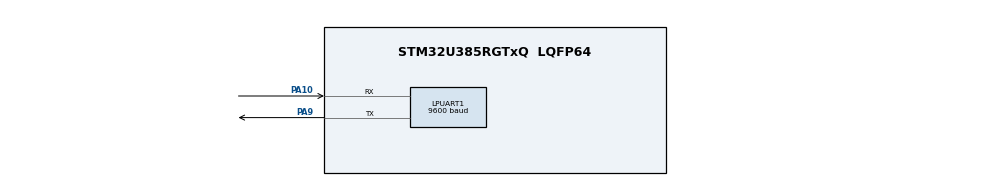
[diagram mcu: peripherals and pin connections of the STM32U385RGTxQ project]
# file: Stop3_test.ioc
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ADC1.Channel-0\#ChannelRegularConversion=ADC_CHANNEL_VREFINT
ADC1.Channel-1\#ChannelRegularConversion=ADC_CHANNEL_TEMPSENSOR
ADC1.EnableAnalogWatchDog1=false
ADC1.LowPowerAutoWait=ENABLE
ADC1.MonitoredBy-0\#ChannelRegularConversion=__NULL
ADC1.MonitoredBy-1\#ChannelRegularConversion=__NULL
ADC1.NbrOfConversion=2
ADC1.NbrOfConversionFlag=1
ADC1.OffsetNumber-0\#ChannelRegularConversion=ADC_OFFSET_NONE
ADC1.OffsetNumber-1\#ChannelRegularConversion=ADC_OFFSET_NONE
ADC1.Rank-0\#ChannelRegularConversion=1
ADC1.Rank-1\#ChannelRegularConversion=2
ADC1.SamplingTime-0\#ChannelRegularConversion=ADC_SAMPLETIME_46CYCLES_5
ADC1.SamplingTime-1\#ChannelRegularConversion=ADC_SAMPLETIME_46CYCLES_5
ADC1.master=1
CORTEX_M33_NS.userName=CORTEX_M33
LPUART1.BaudRate=9600
LPUART1.FIFOMode=UART_FIFOMODE_ENABLE
LPUART1.RXFIFOThreshold=UART_RXFIFO_THRESHOLD_8_8
LPUART1.TXFIFOThreshold=UART_TXFIFO_THRESHOLD_8_8
Mcu.Family=STM32U3
Mcu.Name=STM32U385RGTxQ
Mcu.Package=LQFP64
NVIC.LPUART1_IRQn=true\:0\:0\:false\:false\:true\:true\:true\:true
NVIC.PriorityGroup=NVIC_PRIORITYGROUP_4
NVIC.RTC_IRQn=true\:0\:0\:false\:false\:true\:true\:true\:true
PA10.Mode=Asynchronous
PA10.Signal=LPUART1_RX
PA9.Mode=Asynchronous
PA9.Signal=LPUART1_TX
PC14-OSC32_IN\ (PC14).Mode=LSE-External-Oscillator
PC14-OSC32_IN\ (PC14).Signal=RCC_OSC32_IN
PC15-OSC32_OUT\ (PC15).Mode=LSE-External-Oscillator
PC15-OSC32_OUT\ (PC15).Signal=RCC_OSC32_OUT
ProjectManager.HeapSize=0x200
ProjectManager.StackSize=0x400
ProjectManager.TargetToolchain=STM32CubeIDE
RCC.ADCFreq_Value=24000000
RCC.ADC_DIV=RCC_ADCDACCLK_DIV2
RCC.AHBFreq_Value=48000000
RCC.APB1Freq_Value=48000000
RCC.APB1TimFreq_Value=48000000
RCC.APB2Freq_Value=48000000
RCC.APB2TimFreq_Value=48000000
RCC.APB3Freq_Value=48000000
RCC.CortexFreq_Value=6000000
RCC.HCLKFreq_Value=48000000
RCC.HSE_VALUE=16000000
RCC.HSI48_VALUE=48000000
RCC.HSI_VALUE=16000000
RCC.LPUART1CLockSelection=RCC_LPUART1CLKSOURCE_LSE
RCC.LSIDIV_VALUE=32000
RCC.MSIKDIV=RCC_MSI_DIV8
RCC.MSIKSource=RCC_MSI_RC1
RCC.MSISDIV=RCC_MSI_DIV2
RCC.RTCClockSelection=RCC_RTCCLKSOURCE_LSE
RCC.SYSCLKFreq_VALUE=48000000
RCC.USBFreq_Value=48000000
RTC.WakeUpClock-WakeUp=RTC_WAKEUPCLOCK_CK_SPRE_16BITS
VP_ADC1_TempSens_Input.Mode=IN-TempSens
VP_ADC1_Vref_Input.Mode=IN-Vrefint
VP_ICACHE_VS_ICACHE.Mode=DirectMappedCache
VP_PWR_VS_DBSignals.Mode=DisableDeadBatterySignals
VP_PWR_VS_LPOM.Mode=PowerOptimisation
VP_PWR_VS_SECSignals.Mode=Security/Privilege
VP_RTC_VS_RTC_Activate.Mode=RTC_Enabled
VP_RTC_VS_RTC_WakeUp_intern.Mode=WakeUp
board=custom

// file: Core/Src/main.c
/* USER CODE BEGIN Header */
/**
  ******************************************************************************
  * @file           : main.c
  * @brief          : Main program body
  ******************************************************************************
  * @attention
  *
  * Copyright (c) 2025 STMicroelectronics.
  * All rights reserved.
  *
  * This software is licensed under terms that can be found in the LICENSE file
  * in the root directory of this software component.
  * If no LICENSE file comes with this software, it is provided AS-IS.
  *
  ******************************************************************************
  */
/* USER CODE END Header */
#include "main.h"

/* USER CODE BEGIN Includes */
#include "stm32u3xx_ll_gpio.h"
#include "stm32u3xx_ll_lpuart.h"
#include "stdio.h"
/* USER CODE END Includes */

ADC_HandleTypeDef hadc1;

UART_HandleTypeDef hlpuart1;

RTC_HandleTypeDef hrtc;

/* USER CODE BEGIN PV */
volatile uint16_t adcVref = 0;
volatile uint16_t adcTemp = 0;

volatile uint16_t Vref = 0;
volatile int16_t Temp = 0;

char TXbuffer[8];
uint8_t length;
uint8_t i = 0;
/* USER CODE END PV */

void SystemClock_Config(void);
static void MX_GPIO_Init(void);
static void MX_RTC_Init(void);
static void MX_ICACHE_Init(void);
static void MX_ADC1_Init(void);
static void MX_LPUART1_UART_Init(void);

int main(void)
{

  /* MCU Configuration--------------------------------------------------------*/

  /* Reset of all peripherals, Initializes the Flash interface and the Systick. */
  HAL_Init();

  /* Configure the system clock */
  SystemClock_Config();

  /* USER CODE BEGIN SysInit */
  /* Enable the SMPS regulator to improve power efficiency */
  if(HAL_PWREx_ConfigSupply(PWR_SMPS_SUPPLY) != HAL_OK)
  {
	  Error_Handler();
  }
  /* USER CODE END SysInit */

  /* Initialize all configured peripherals */
  MX_GPIO_Init();
  MX_RTC_Init();
  MX_ICACHE_Init();
  MX_ADC1_Init();
  MX_LPUART1_UART_Init();
  /* USER CODE BEGIN 2 */

  /* Run ADC calibration*/
    if(HAL_ADCEx_Calibration_Start(&hadc1, ADC_SINGLE_ENDED) != HAL_OK)
    {
          Error_Handler();
    }

  /*Flash in power down mode during Stop mode - by default after reset */
  HAL_PWREx_DisableFlashFastWakeUp();

  /*Reduce SRAM2 retention to 8 kB*/
  HAL_PWREx_DisableRAMsContentStopRetention(PWR_SRAM2_PAGE2_STOP_RETENTION); // reduction -600nA
  HAL_PWREx_DisableRAMsContentStopRetention(PWR_SRAM2_PAGE3_STOP_RETENTION);
  HAL_PWREx_DisableRAMsContentStopRetention(PWR_FDCAN_USB_STOP_RETENTION);
  HAL_PWREx_DisableRAMsContentStopRetention(PWR_PKA_STOP_RETENTION);

  /*Put full SRAM1 in power down mode*/
  HAL_PWREx_EnableRAMsPowerDown(PWR_SRAM1_POWERDOWN); // reduction - 500nA

  /* Configure RTC wake up source for STop3 mode - RM Table 78. PWR wake-up source selection IN*/
  HAL_PWR_EnableWakeUpLine(PWR_WAKEUP_LINE7, PWR_WAKEUP_SELECT_3, PWR_WAKEUP_POLARITY_HIGH);
  /* USER CODE END 2 */

  /* Infinite loop */
  /* USER CODE BEGIN WHILE */
  while (1)
  {
	  HAL_ADC_Start(&hadc1);
	  	  HAL_ADC_PollForConversion(&hadc1, 1);
	  	  adcVref = HAL_ADC_GetValue(&hadc1);

	  	  /*Helper macro to calculate analog reference voltage (Vref+) unit: mVolt */
	  	  Vref = __LL_ADC_CALC_VREFANALOG_VOLTAGE(adcVref,LL_ADC_RESOLUTION_12B);

	  	  HAL_ADC_PollForConversion(&hadc1, 1);
	  	  adcTemp = HAL_ADC_GetValue(&hadc1);

	  	  /*Helper macro to calculate Temperature, unit: degree Celsius */
	  	  Temp = __LL_ADC_CALC_TEMPERATURE(Vref, adcTemp, LL_ADC_RESOLUTION_12B);

	  	  //HAL_ADCEx_EnterADCDeepPowerDownMode(&hadc1);

	  	/* Convert integers to string with comma and carriage return */
	  //	length = sprintf(TXbuffer, "%d,%d\r", Vref, Temp);

	  	/*TX data w/o FIFO
	  	* expected time spend in Run mode ~ 1ms
	  	* */
	  //	HAL_UART_Transmit(&hlpuart1, (uint8_t*)TXbuffer, length, 100);

	  	/* Enable MCU wake-up by LPUART */
	  	HAL_UARTEx_EnableStopMode(&hlpuart1);

	  	/* Enable IT for Transfer Complete = 8 bytes in our case*/
	  	LL_LPUART_ClearFlag_TC(LPUART1);
	  	LL_LPUART_EnableIT_TC(LPUART1);
	  	__HAL_UART_CLEAR_IT(&hlpuart1, UART_CLEAR_TCF);
	  	__HAL_UART_ENABLE_IT(&hlpuart1,UART_IT_TC);

	  	/*TX data w/ FIFO */
	  	/* Convert integers to string with comma and carriage return */
	  	length = sprintf(TXbuffer, "%d,%d\r", Vref, Temp);
	  	i = 0;
	  	while(__HAL_UART_GET_FLAG(&hlpuart1, UART_FLAG_TXFNF))
	  	 	 {
	  	 		 LPUART1->TDR = (uint8_t)TXbuffer[i];
	  	 		 i++;
	  	 	 }
	  	HAL_PWR_EnterSTOPMode(PWR_LOWPOWERMODE_STOP2, PWR_STOPENTRY_WFI);

	  /*Clear all wakeup source flags*/
	  __HAL_PWR_CLEAR_FLAG(PWR_WAKEUP_ALL_FLAG);

	  /* Enter STOP 3 mode */
	  HAL_PWR_EnterSTOPMode(PWR_LOWPOWERMODE_STOP3, PWR_STOPENTRY_WFI);
    /* USER CODE END WHILE */

  }
}

void SystemClock_Config(void)
{
  RCC_OscInitTypeDef RCC_OscInitStruct = {0};
  RCC_ClkInitTypeDef RCC_ClkInitStruct = {0};

  /** Enable Epod Booster
  */
  if (HAL_RCCEx_EpodBoosterClkConfig(RCC_EPODBOOSTER_SOURCE_MSIS, RCC_EPODBOOSTER_DIV1) != HAL_OK)
  {
    Error_Handler();
  }
  if (HAL_PWREx_EnableEpodBooster() != HAL_OK)
  {
    Error_Handler();
  }

  /** Configure the main internal regulator output voltage
  */
  if (HAL_PWREx_ControlVoltageScaling(PWR_REGULATOR_VOLTAGE_SCALE2) != HAL_OK)
  {
    Error_Handler();
  }

  /** Set Flash latency before increasing MSIS
  */
  __HAL_FLASH_SET_LATENCY(FLASH_LATENCY_2);

  /** Configure LSE Drive Capability
  */
  HAL_PWR_EnableBkUpAccess();
  __HAL_RCC_LSEDRIVE_CONFIG(RCC_LSEDRIVE_LOW);

  /** Initializes the CPU, AHB and APB buses clocks
  */
  RCC_OscInitStruct.OscillatorType = RCC_OSCILLATORTYPE_LSE|RCC_OSCILLATORTYPE_MSIS;
  RCC_OscInitStruct.LSEState = RCC_LSE_ON;
  RCC_OscInitStruct.MSISState = RCC_MSI_ON;
  RCC_OscInitStruct.MSISSource = RCC_MSI_RC0;
  RCC_OscInitStruct.MSISDiv = RCC_MSI_DIV2;
  if (HAL_RCC_OscConfig(&RCC_OscInitStruct) != HAL_OK)
  {
    Error_Handler();
  }

  /** Initializes the CPU, AHB and APB buses clocks
  */
  RCC_ClkInitStruct.ClockType = RCC_CLOCKTYPE_HCLK|RCC_CLOCKTYPE_SYSCLK
                              |RCC_CLOCKTYPE_PCLK1|RCC_CLOCKTYPE_PCLK2
                              |RCC_CLOCKTYPE_PCLK3;
  RCC_ClkInitStruct.SYSCLKSource = RCC_SYSCLKSOURCE_MSIS;
  RCC_ClkInitStruct.AHBCLKDivider = RCC_SYSCLK_DIV1;
  RCC_ClkInitStruct.APB1CLKDivider = RCC_HCLK_DIV1;
  RCC_ClkInitStruct.APB2CLKDivider = RCC_HCLK_DIV1;
  RCC_ClkInitStruct.APB3CLKDivider = RCC_HCLK_DIV1;

  if (HAL_RCC_ClockConfig(&RCC_ClkInitStruct, FLASH_LATENCY_2) != HAL_OK)
  {
    Error_Handler();
  }
}

static void MX_ADC1_Init(void)
{

  ADC_ChannelConfTypeDef sConfig = {0};

  /** Common config
  */
  hadc1.Instance = ADC1;
  hadc1.Init.Resolution = ADC_RESOLUTION_12B;
  hadc1.Init.GainCompensation = 0;
  hadc1.Init.ScanConvMode = ADC_SCAN_ENABLE;
  hadc1.Init.EOCSelection = ADC_EOC_SINGLE_CONV;
  hadc1.Init.LowPowerAutoWait = ENABLE;
  hadc1.Init.ContinuousConvMode = DISABLE;
  hadc1.Init.NbrOfConversion = 2;
  hadc1.Init.DiscontinuousConvMode = DISABLE;
  hadc1.Init.ExternalTrigConv = ADC_SOFTWARE_START;
  hadc1.Init.ExternalTrigConvEdge = ADC_EXTERNALTRIGCONVEDGE_NONE;
  hadc1.Init.Overrun = ADC_OVR_DATA_PRESERVED;
  hadc1.Init.LeftBitShift = ADC_LEFTBITSHIFT_NONE;
  hadc1.Init.ConversionDataManagement = ADC_CONVERSIONDATA_DR;
  hadc1.Init.OversamplingMode = DISABLE;
  if (HAL_ADC_Init(&hadc1) != HAL_OK)
  {
    Error_Handler();
  }

  /** Configure Regular Channel
  */
  sConfig.Channel = ADC_CHANNEL_VREFINT;
  sConfig.Rank = ADC_REGULAR_RANK_1;
  sConfig.SamplingTime = ADC_SAMPLETIME_46CYCLES_5;
  sConfig.OffsetNumber = ADC_OFFSET_NONE;
  sConfig.Offset = 0;
  if (HAL_ADC_ConfigChannel(&hadc1, &sConfig) != HAL_OK)
  {
    Error_Handler();
  }

  /** Configure Regular Channel
  */
  sConfig.Channel = ADC_CHANNEL_TEMPSENSOR;
  sConfig.Rank = ADC_REGULAR_RANK_2;
  if (HAL_ADC_ConfigChannel(&hadc1, &sConfig) != HAL_OK)
  {
    Error_Handler();
  }

}

static void MX_ICACHE_Init(void)
{

  /** Enable instruction cache in 1-way (direct mapped cache)
  */
  if (HAL_ICACHE_ConfigAssociativityMode(ICACHE_1WAY) != HAL_OK)
  {
    Error_Handler();
  }
  if (HAL_ICACHE_Enable() != HAL_OK)
  {
    Error_Handler();
  }

}

static void MX_LPUART1_UART_Init(void)
{

  hlpuart1.Instance = LPUART1;
  hlpuart1.Init.BaudRate = 9600;
  hlpuart1.Init.WordLength = UART_WORDLENGTH_8B;
  hlpuart1.Init.StopBits = UART_STOPBITS_1;
  hlpuart1.Init.Parity = UART_PARITY_NONE;
  hlpuart1.Init.Mode = UART_MODE_TX_RX;
  hlpuart1.Init.HwFlowCtl = UART_HWCONTROL_NONE;
  hlpuart1.Init.OneBitSampling = UART_ONE_BIT_SAMPLE_DISABLE;
  hlpuart1.Init.ClockPrescaler = UART_PRESCALER_DIV1;
  hlpuart1.AdvancedInit.AdvFeatureInit = UART_ADVFEATURE_NO_INIT;
  hlpuart1.FifoMode = UART_FIFOMODE_ENABLE;
  if (HAL_UART_Init(&hlpuart1) != HAL_OK)
  {
    Error_Handler();
  }
  if (HAL_UARTEx_SetTxFifoThreshold(&hlpuart1, UART_TXFIFO_THRESHOLD_8_8) != HAL_OK)
  {
    Error_Handler();
  }
  if (HAL_UARTEx_SetRxFifoThreshold(&hlpuart1, UART_RXFIFO_THRESHOLD_8_8) != HAL_OK)
  {
    Error_Handler();
  }
  if (HAL_UARTEx_EnableFifoMode(&hlpuart1) != HAL_OK)
  {
    Error_Handler();
  }

}

static void MX_RTC_Init(void)
{

  RTC_PrivilegeStateTypeDef privilegeState = {0};

  /** Initialize RTC Only
  */
  hrtc.Instance = RTC;
  hrtc.Init.HourFormat = RTC_HOURFORMAT_24;
  hrtc.Init.AsynchPrediv = 127;
  hrtc.Init.SynchPrediv = 255;
  hrtc.Init.OutPut = RTC_OUTPUT_DISABLE;
  hrtc.Init.OutPutRemap = RTC_OUTPUT_REMAP_NONE;
  hrtc.Init.OutPutPolarity = RTC_OUTPUT_POLARITY_HIGH;
  hrtc.Init.OutPutType = RTC_OUTPUT_TYPE_OPENDRAIN;
  hrtc.Init.OutPutPullUp = RTC_OUTPUT_PULLUP_NONE;
  hrtc.Init.BinMode = RTC_BINARY_NONE;
  if (HAL_RTC_Init(&hrtc) != HAL_OK)
  {
    Error_Handler();
  }
  privilegeState.rtcPrivilegeFull = RTC_PRIVILEGE_FULL_NO;
  privilegeState.backupRegisterPrivZone = RTC_PRIVILEGE_BKUP_ZONE_NONE;
  privilegeState.backupRegisterStartZone2 = RTC_BKP_DR0;
  privilegeState.backupRegisterStartZone3 = RTC_BKP_DR0;
  if (HAL_RTCEx_PrivilegeModeSet(&hrtc, &privilegeState) != HAL_OK)
  {
    Error_Handler();
  }

  /** Enable the WakeUp
  */
  if (HAL_RTCEx_SetWakeUpTimer_IT(&hrtc, 0, RTC_WAKEUPCLOCK_CK_SPRE_16BITS, 0) != HAL_OK)
  {
    Error_Handler();
  }

}

static void MX_GPIO_Init(void)
{

  /* GPIO Ports Clock Enable */
  __HAL_RCC_GPIOC_CLK_ENABLE();
  __HAL_RCC_GPIOA_CLK_ENABLE();

}

void Error_Handler(void)
{
  __disable_irq();
  while (1)
  {
  }
}
